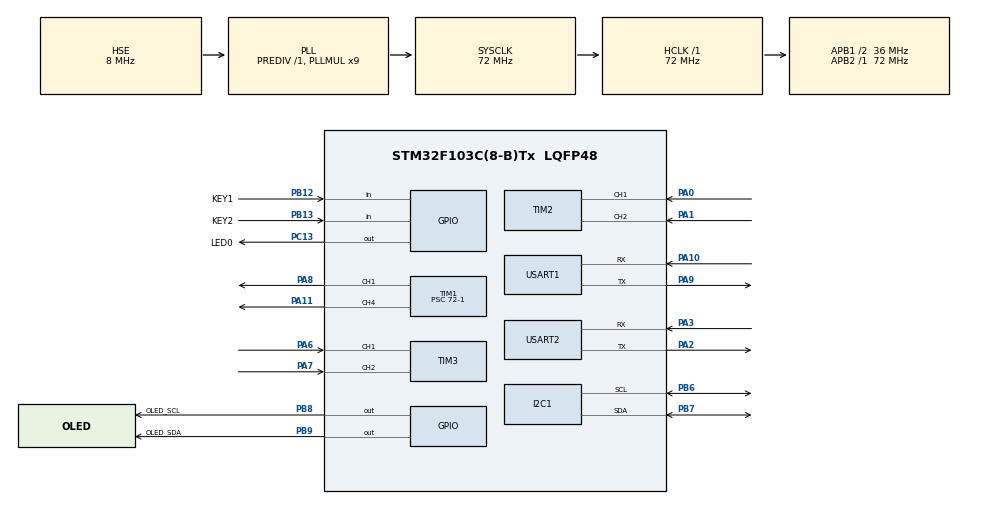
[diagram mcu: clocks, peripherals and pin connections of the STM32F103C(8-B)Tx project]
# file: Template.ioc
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Dma.Request0=USART1_RX
Dma.Request1=USART1_TX
Dma.Request2=USART2_RX
Dma.Request3=USART2_TX
Dma.USART1_RX.0.Direction=DMA_PERIPH_TO_MEMORY
Dma.USART1_RX.0.Instance=DMA1_Channel5
Dma.USART1_RX.0.MemDataAlignment=DMA_MDATAALIGN_BYTE
Dma.USART1_RX.0.MemInc=DMA_MINC_ENABLE
Dma.USART1_RX.0.Mode=DMA_NORMAL
Dma.USART1_RX.0.PeriphDataAlignment=DMA_PDATAALIGN_BYTE
Dma.USART1_RX.0.PeriphInc=DMA_PINC_DISABLE
Dma.USART1_RX.0.Priority=DMA_PRIORITY_LOW
Dma.USART1_TX.1.Direction=DMA_MEMORY_TO_PERIPH
Dma.USART1_TX.1.Instance=DMA1_Channel4
Dma.USART1_TX.1.MemDataAlignment=DMA_MDATAALIGN_BYTE
Dma.USART1_TX.1.MemInc=DMA_MINC_ENABLE
Dma.USART1_TX.1.Mode=DMA_NORMAL
Dma.USART1_TX.1.PeriphDataAlignment=DMA_PDATAALIGN_BYTE
Dma.USART1_TX.1.PeriphInc=DMA_PINC_DISABLE
Dma.USART1_TX.1.Priority=DMA_PRIORITY_LOW
Dma.USART2_RX.2.Direction=DMA_PERIPH_TO_MEMORY
Dma.USART2_RX.2.Instance=DMA1_Channel6
Dma.USART2_RX.2.MemDataAlignment=DMA_MDATAALIGN_BYTE
Dma.USART2_RX.2.MemInc=DMA_MINC_ENABLE
Dma.USART2_RX.2.Mode=DMA_NORMAL
Dma.USART2_RX.2.PeriphDataAlignment=DMA_PDATAALIGN_BYTE
Dma.USART2_RX.2.PeriphInc=DMA_PINC_DISABLE
Dma.USART2_RX.2.Priority=DMA_PRIORITY_LOW
Dma.USART2_TX.3.Direction=DMA_MEMORY_TO_PERIPH
Dma.USART2_TX.3.Instance=DMA1_Channel7
Dma.USART2_TX.3.MemDataAlignment=DMA_MDATAALIGN_BYTE
Dma.USART2_TX.3.MemInc=DMA_MINC_ENABLE
Dma.USART2_TX.3.Mode=DMA_NORMAL
Dma.USART2_TX.3.PeriphDataAlignment=DMA_PDATAALIGN_BYTE
Dma.USART2_TX.3.PeriphInc=DMA_PINC_DISABLE
Dma.USART2_TX.3.Priority=DMA_PRIORITY_LOW
Mcu.Family=STM32F1
Mcu.Name=STM32F103C(8-B)Tx
Mcu.Package=LQFP48
NVIC.DMA1_Channel4_IRQn=true\:0\:0\:false\:false\:true\:false\:true\:true
NVIC.DMA1_Channel5_IRQn=true\:0\:0\:false\:false\:true\:false\:true\:true
NVIC.DMA1_Channel6_IRQn=true\:0\:0\:false\:false\:true\:false\:true\:true
NVIC.DMA1_Channel7_IRQn=true\:0\:0\:false\:false\:true\:false\:true\:true
NVIC.PriorityGroup=NVIC_PRIORITYGROUP_2
NVIC.USART1_IRQn=true\:0\:0\:false\:false\:true\:true\:true\:true
NVIC.USART2_IRQn=true\:0\:0\:false\:false\:true\:true\:true\:true
PA0-WKUP.Signal=S_TIM2_CH1_ETR
PA1.Signal=S_TIM2_CH2
PA10.Mode=Asynchronous
PA10.Signal=USART1_RX
PA11.Signal=S_TIM1_CH4
PA13.Mode=Serial_Wire
PA13.Signal=SYS_JTMS-SWDIO
PA14.Mode=Serial_Wire
PA14.Signal=SYS_JTCK-SWCLK
PA2.Mode=Asynchronous
PA2.Signal=USART2_TX
PA3.Mode=Asynchronous
PA3.Signal=USART2_RX
PA6.Signal=S_TIM3_CH1
PA7.Signal=S_TIM3_CH2
PA8.Signal=S_TIM1_CH1
PA9.Mode=Asynchronous
PA9.Signal=USART1_TX
PB12.GPIO_Label=KEY1
PB12.GPIO_PuPd=GPIO_PULLUP
PB12.Signal=GPIO_Input
PB13.GPIO_Label=KEY2
PB13.GPIO_PuPd=GPIO_PULLUP
PB13.Signal=GPIO_Input
PB6.Mode=I2C
PB6.Signal=I2C1_SCL
PB7.Mode=I2C
PB7.Signal=I2C1_SDA
PB8.GPIO_Label=OLED_SCL
PB8.GPIO_Speed=GPIO_SPEED_FREQ_HIGH
PB8.Signal=GPIO_Output
PB9.GPIO_Label=OLED_SDA
PB9.GPIO_Speed=GPIO_SPEED_FREQ_HIGH
PB9.PinState=GPIO_PIN_RESET
PB9.Signal=GPIO_Output
PC13-TAMPER-RTC.GPIO_Label=LED0
PC13-TAMPER-RTC.Signal=GPIO_Output
PC14-OSC32_IN.Mode=LSE-External-Oscillator
PC14-OSC32_IN.Signal=RCC_OSC32_IN
PC15-OSC32_OUT.Mode=LSE-External-Oscillator
PC15-OSC32_OUT.Signal=RCC_OSC32_OUT
PD0-OSC_IN.Mode=HSE-External-Oscillator
PD0-OSC_IN.Signal=RCC_OSC_IN
PD1-OSC_OUT.Mode=HSE-External-Oscillator
PD1-OSC_OUT.Signal=RCC_OSC_OUT
ProjectManager.HeapSize=0x200
ProjectManager.StackSize=0x400
ProjectManager.TargetToolchain=MDK-ARM V5.32
RCC.AHBFreq_Value=72000000
RCC.APB1CLKDivider=RCC_HCLK_DIV2
RCC.APB1Freq_Value=36000000
RCC.APB1TimFreq_Value=72000000
RCC.APB2Freq_Value=72000000
RCC.APB2TimFreq_Value=72000000
RCC.HCLKFreq_Value=72000000
RCC.PLLMUL=RCC_PLL_MUL9
RCC.PLLSourceVirtual=RCC_PLLSOURCE_HSE
RCC.SYSCLKFreq_VALUE=72000000
RCC.SYSCLKSource=RCC_SYSCLKSOURCE_PLLCLK
RCC.USBFreq_Value=72000000
SH.S_TIM1_CH1.0=TIM1_CH1,PWM Generation1 CH1
SH.S_TIM1_CH4.0=TIM1_CH4,PWM Generation4 CH4
SH.S_TIM2_CH1_ETR.0=TIM2_CH1,Encoder_Interface
SH.S_TIM2_CH2.0=TIM2_CH2,Encoder_Interface
SH.S_TIM3_CH1.0=TIM3_CH1,Encoder_Interface
SH.S_TIM3_CH2.0=TIM3_CH2,Encoder_Interface
TIM1.AutoReloadPreload=TIM_AUTORELOAD_PRELOAD_ENABLE
TIM1.Channel-PWM\ Generation1\ CH1=TIM_CHANNEL_1
TIM1.Channel-PWM\ Generation4\ CH4=TIM_CHANNEL_4
TIM1.Period=100-1
TIM1.Prescaler=72-1
TIM2.EncoderMode=TIM_ENCODERMODE_TI12
TIM3.EncoderMode=TIM_ENCODERMODE_TI12
USART1.VirtualMode=VM_ASYNC
USART2.VirtualMode=VM_ASYNC
VP_TIM1_VS_ClockSourceINT.Mode=Internal
board=custom

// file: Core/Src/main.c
/* USER CODE BEGIN Header */
/**
  ******************************************************************************
  * @file           : main.c
  * @brief          : Main program body
  ******************************************************************************
  * @attention
  *
  * Copyright (c) 2025 STMicroelectronics.
  * All rights reserved.
  *
  * This software is licensed under terms that can be found in the LICENSE file
  * in the root directory of this software component.
  * If no LICENSE file comes with this software, it is provided AS-IS.
  *
  ******************************************************************************
  */
/* USER CODE END Header */
#include "main.h"
#include "dma.h"
#include "i2c.h"
#include "tim.h"
#include "usart.h"
#include "gpio.h"

void SystemClock_Config(void);

/* USER CODE BEGIN 0 */

// *******************库导入开始*******************

#include "Mymain.h"

// *******************库导入结束*******************

/* USER CODE END 0 */

int main(void)
{
  /* USER CODE BEGIN 1 */

	// 暂时关闭 SysTick 中断,否则可能导致某些功能还没有进行初始化就驱动,导致指针指向空,发生越界错误
  __disable_irq();

  /* USER CODE END 1 */

  /* MCU Configuration--------------------------------------------------------*/

  /* Reset of all peripherals, Initializes the Flash interface and the Systick. */
  HAL_Init();

  /* Configure the system clock */
  SystemClock_Config();

  /* Initialize all configured peripherals */
  MX_GPIO_Init();
  MX_DMA_Init();
  MX_USART1_UART_Init();
  MX_TIM2_Init();
  MX_TIM3_Init();
  MX_USART2_UART_Init();
  MX_I2C1_Init();
  MX_TIM1_Init();
  /* USER CODE BEGIN 2 */

	// ******************* setup 开始*******************

	Mymain() ;

	// ******************* setup 结束*******************

  /* USER CODE END 2 */

  /* Infinite loop */
  while (1)
  {

  }
}

void SystemClock_Config(void)
{
  RCC_OscInitTypeDef RCC_OscInitStruct = {0};
  RCC_ClkInitTypeDef RCC_ClkInitStruct = {0};

  /** Initializes the RCC Oscillators according to the specified parameters
  * in the RCC_OscInitTypeDef structure.
  */
  RCC_OscInitStruct.OscillatorType = RCC_OSCILLATORTYPE_HSE;
  RCC_OscInitStruct.HSEState = RCC_HSE_ON;
  RCC_OscInitStruct.HSEPredivValue = RCC_HSE_PREDIV_DIV1;
  RCC_OscInitStruct.HSIState = RCC_HSI_ON;
  RCC_OscInitStruct.PLL.PLLState = RCC_PLL_ON;
  RCC_OscInitStruct.PLL.PLLSource = RCC_PLLSOURCE_HSE;
  RCC_OscInitStruct.PLL.PLLMUL = RCC_PLL_MUL9;
  if (HAL_RCC_OscConfig(&RCC_OscInitStruct) != HAL_OK)
  {
    Error_Handler();
  }

  /** Initializes the CPU, AHB and APB buses clocks
  */
  RCC_ClkInitStruct.ClockType = RCC_CLOCKTYPE_HCLK|RCC_CLOCKTYPE_SYSCLK
                              |RCC_CLOCKTYPE_PCLK1|RCC_CLOCKTYPE_PCLK2;
  RCC_ClkInitStruct.SYSCLKSource = RCC_SYSCLKSOURCE_PLLCLK;
  RCC_ClkInitStruct.AHBCLKDivider = RCC_SYSCLK_DIV1;
  RCC_ClkInitStruct.APB1CLKDivider = RCC_HCLK_DIV2;
  RCC_ClkInitStruct.APB2CLKDivider = RCC_HCLK_DIV1;

  if (HAL_RCC_ClockConfig(&RCC_ClkInitStruct, FLASH_LATENCY_2) != HAL_OK)
  {
    Error_Handler();
  }
}

void Error_Handler(void)
{
  __disable_irq();
  while (1)
  {
  }
}
